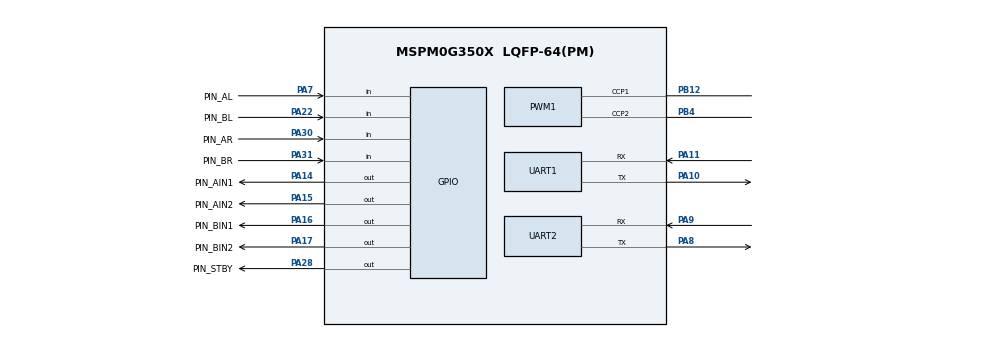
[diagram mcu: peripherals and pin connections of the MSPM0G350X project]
/**
 *
 * @cliArgs --device "MSPM0G350X" --part "Default" --package "LQFP-64(PM)" --product "mspm0_sdk@2.09.00.02"
 * @versions {"tool":"1.28.0+4696"}
 */

/**
 * Import the modules used in this configuration.
 */
const GPIO          = scripting.addModule("/ti/driverlib/GPIO", {}, false);
const GPIO1         = GPIO.addInstance();
const GPIO2         = GPIO.addInstance();
const GPIO3         = GPIO.addInstance();
const GPIO4         = GPIO.addInstance();
const GPIO5         = GPIO.addInstance();
const PWM           = scripting.addModule("/ti/driverlib/PWM", {}, false);
const PWM1          = PWM.addInstance();
const SYSCTL        = scripting.addModule("/ti/driverlib/SYSCTL");
const UART          = scripting.addModule("/ti/driverlib/UART", {}, false);
const UART1         = UART.addInstance();
const UART2         = UART.addInstance();
const ProjectConfig = scripting.addModule("/ti/project_config/ProjectConfig");

/**
 * Write custom configuration values to the imported modules.
 */
GPIO1.$name                         = "A";
GPIO1.associatedPins.create(2);
GPIO1.associatedPins[0].$name       = "PIN_AIN1";
GPIO1.associatedPins[0].pin.$assign = "PA14";
GPIO1.associatedPins[1].$name       = "PIN_AIN2";
GPIO1.associatedPins[1].pin.$assign = "PA15";

const Board = scripting.addModule("/ti/driverlib/Board", {}, false);

GPIO2.$name                         = "B";
GPIO2.associatedPins.create(2);
GPIO2.associatedPins[0].$name       = "PIN_BIN1";
GPIO2.associatedPins[0].pin.$assign = "PA16";
GPIO2.associatedPins[1].$name       = "PIN_BIN2";
GPIO2.associatedPins[1].pin.$assign = "PA17";

GPIO3.$name                         = "STBY";
GPIO3.associatedPins[0].$name       = "PIN_STBY";
GPIO3.associatedPins[0].pin.$assign = "PA28";

GPIO4.$name                         = "ENC_A";
GPIO4.associatedPins.create(2);
GPIO4.associatedPins[0].$name       = "PIN_AL";
GPIO4.associatedPins[0].direction   = "INPUT";
GPIO4.associatedPins[0].interruptEn = true;
GPIO4.associatedPins[0].polarity    = "RISE_FALL";
GPIO4.associatedPins[0].pin.$assign = "PA7";
GPIO4.associatedPins[1].$name       = "PIN_AR";
GPIO4.associatedPins[1].direction   = "INPUT";
GPIO4.associatedPins[1].interruptEn = true;
GPIO4.associatedPins[1].polarity    = "RISE_FALL";
GPIO4.associatedPins[1].pin.$assign = "PA30";

GPIO5.$name                         = "ENC_B";
GPIO5.associatedPins.create(2);
GPIO5.associatedPins[0].$name       = "PIN_BL";
GPIO5.associatedPins[0].direction   = "INPUT";
GPIO5.associatedPins[0].pin.$assign = "PA22";
GPIO5.associatedPins[1].$name       = "PIN_BR";
GPIO5.associatedPins[1].direction   = "INPUT";
GPIO5.associatedPins[1].polarity    = "RISE_FALL";
GPIO5.associatedPins[1].pin.$assign = "PA31";

PWM1.$name                              = "PWM_TB1";
PWM1.timerCount                         = 1600;
PWM1.ccIndex                            = [1,2];
PWM1.ccp1PinConfig.$name                = "ti_driverlib_gpio_GPIOPinGeneric1";
PWM1.ccp1PinConfig.direction            = scripting.forceWrite("OUTPUT");
PWM1.ccp1PinConfig.hideOutputInversion  = scripting.forceWrite(false);
PWM1.ccp1PinConfig.onlyInternalResistor = scripting.forceWrite(false);
PWM1.ccp1PinConfig.passedPeripheralType = scripting.forceWrite("Digital");
PWM1.peripheral.$assign                 = "TIMA0";
PWM1.peripheral.ccp1Pin.$assign         = "PB12";
PWM1.peripheral.ccp2Pin.$assign         = "PB4";
PWM1.PWM_CHANNEL_2.$name                = "ti_driverlib_pwm_PWMTimerCC1";
PWM1.ccp2PinConfig.$name                = "ti_driverlib_gpio_GPIOPinGeneric0";
PWM1.PWM_CHANNEL_1.$name                = "ti_driverlib_pwm_PWMTimerCC0";


UART1.$name                            = "UART_DEBUG";
UART1.targetBaudRate                   = 115200;
UART1.peripheral.$assign               = "UART0";
UART1.peripheral.rxPin.$assign         = "PA11";
UART1.peripheral.txPin.$assign         = "PA10";
UART1.txPinConfig.$name                = "ti_driverlib_gpio_GPIOPinGeneric2";
UART1.txPinConfig.direction            = scripting.forceWrite("OUTPUT");
UART1.txPinConfig.hideOutputInversion  = scripting.forceWrite(false);
UART1.txPinConfig.onlyInternalResistor = scripting.forceWrite(false);
UART1.txPinConfig.passedPeripheralType = scripting.forceWrite("Digital");
UART1.rxPinConfig.$name                = "ti_driverlib_gpio_GPIOPinGeneric3";
UART1.rxPinConfig.hideOutputInversion  = scripting.forceWrite(false);
UART1.rxPinConfig.onlyInternalResistor = scripting.forceWrite(false);
UART1.rxPinConfig.passedPeripheralType = scripting.forceWrite("Digital");

UART2.$name                            = "UART_BLUETOOTH";
UART2.targetBaudRate                   = 115200;
UART2.enabledInterrupts                = ["RX"];
UART2.peripheral.$assign               = "UART1";
UART2.peripheral.rxPin.$assign         = "PA9";
UART2.peripheral.txPin.$assign         = "PA8";
UART2.txPinConfig.$name                = "ti_driverlib_gpio_GPIOPinGeneric4";
UART2.txPinConfig.direction            = scripting.forceWrite("OUTPUT");
UART2.txPinConfig.hideOutputInversion  = scripting.forceWrite(false);
UART2.txPinConfig.onlyInternalResistor = scripting.forceWrite(false);
UART2.txPinConfig.passedPeripheralType = scripting.forceWrite("Digital");
UART2.rxPinConfig.$name                = "ti_driverlib_gpio_GPIOPinGeneric5";
UART2.rxPinConfig.hideOutputInversion  = scripting.forceWrite(false);
UART2.rxPinConfig.onlyInternalResistor = scripting.forceWrite(false);
UART2.rxPinConfig.passedPeripheralType = scripting.forceWrite("Digital");

ProjectConfig.deviceSpin = "MSPM0G3507";

/**
 * Pinmux solution for unlocked pins/peripherals. This ensures that minor changes to the automatic solver in a future
 * version of the tool will not impact the pinmux you originally saw.  These lines can be completely deleted in order to
 * re-solve from scratch.
 */
Board.peripheral.$suggestSolution          = "DEBUGSS";
Board.peripheral.swclkPin.$suggestSolution = "PA20";
Board.peripheral.swdioPin.$suggestSolution = "PA19";
SYSCTL.peripheral.$suggestSolution         = "SYSCTL";
